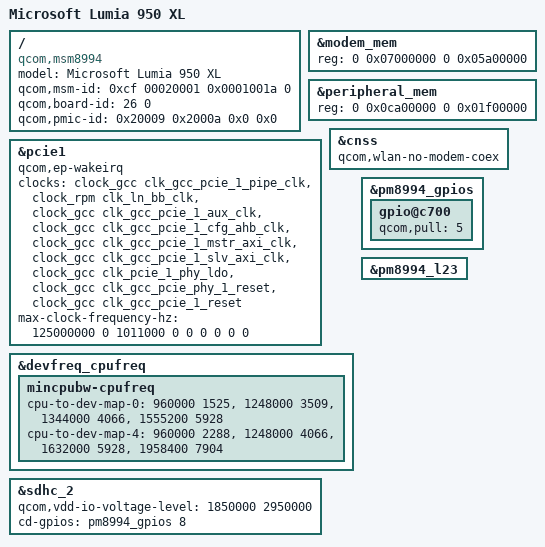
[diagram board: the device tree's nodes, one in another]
/* Copyright (c) 2014-2015, The Linux Foundation. All rights reserved.
 *
 * This program is free software; you can redistribute it and/or modify
 * it under the terms of the GNU General Public License version 2 and
 * only version 2 as published by the Free Software Foundation.
 *
 * This program is distributed in the hope that it will be useful,
 * but WITHOUT ANY WARRANTY; without even the implied warranty of
 * MERCHANTABILITY or FITNESS FOR A PARTICULAR PURPOSE.  See the
 * GNU General Public License for more details.
 */

/dts-v1/;

#include "../qcom/msm8994-v2.1.dtsi"
#include "../qcom/msm8994-pinctrl.dtsi"
#include "msm8994-chi.dtsi"
#include "cityman-audio.dtsi"

/ {
	model = "Microsoft Lumia 950 XL";
	compatible = "qcom,msm8994", "mmo,cityman";
	qcom,msm-id = <0xcf 00020001 0x0001001a 0>;
	qcom,board-id = <26 0>;
	qcom,pmic-id = <0x20009 0x2000a 0x0 0x0>;
};

/*
 * Keep the stock cityman modem load addresses out of Linux allocations.
 * ramoops uses the common region at the top of DDR bank 1, clear of the
 * modem image.
 */
&modem_mem {
	reg = <0 0x07000000 0 0x05a00000>;
};

&peripheral_mem {
	reg = <0 0x0ca00000 0 0x01f00000>;
};

/* Reset the controller as well as the PHY before enumerating QCA6174. */
&pcie1 {
	/* CNSS must power the endpoint before the first enumeration. */
	qcom,ep-wakeirq;
	clocks = <&clock_gcc clk_gcc_pcie_1_pipe_clk>,
		<&clock_rpm clk_ln_bb_clk>,
		<&clock_gcc clk_gcc_pcie_1_aux_clk>,
		<&clock_gcc clk_gcc_pcie_1_cfg_ahb_clk>,
		<&clock_gcc clk_gcc_pcie_1_mstr_axi_clk>,
		<&clock_gcc clk_gcc_pcie_1_slv_axi_clk>,
		<&clock_gcc clk_pcie_1_phy_ldo>,
		<&clock_gcc clk_gcc_pcie_phy_1_reset>,
		<&clock_gcc clk_gcc_pcie_1_reset>;
	clock-names = "pcie_1_pipe_clk", "pcie_1_ref_clk_src",
		"pcie_1_aux_clk", "pcie_1_cfg_ahb_clk",
		"pcie_1_mstr_axi_clk", "pcie_1_slv_axi_clk",
		"pcie_1_ldo", "pcie_1_phy_reset", "core_reset";
	max-clock-frequency-hz = <125000000 0 1011000 0 0 0 0 0 0>;
};

#include "cityman-thermal.dtsi"

/* The stock MPSS asserts in coex_qmb.c with the WLAN WCI-2 coexistence on. */
&cnss {
	qcom,wlan-no-modem-coex;
};

/* DDR floor follows the CPU frequency, so input boosts and launch locks
 * also raise the memory bus (the msm8994 default keeps 200 MHz up to
 * 1.824 GHz). Values are entries of the cpubw bandwidth table. */
&devfreq_cpufreq {
	mincpubw-cpufreq {
		cpu-to-dev-map-0 =
			<  960000  1525 >,
			< 1248000  3509 >,
			< 1344000  4066 >,
			< 1555200  5928 >;
		cpu-to-dev-map-4 =
			<  960000  2288 >,
			< 1248000  4066 >,
			< 1632000  5928 >,
			< 1958400  7904 >;
	};
};

/*
 * microSD (sdhc_2), from the Windows ACPI description of \_SB.SDC2: the card
 * detect line (PM8994 GPIO 8) has no pull, and the low I/O level on LDO13 is
 * 1.85 V, the regulator's floor (common/regulator.dtsi); a 1.8 V request on
 * L13 would fail the UHS voltage switch.
 *
 * The detect line is high with a card in the tray and low with the tray
 * removed (measured on a cityman, 30/10/2026). Declared active low, the slot
 * saw the card for a moment while the tray went in and then dropped it as
 * removed, so the polarity is active high.
 */
&pm8994_gpios {
	gpio@c700 { /* GPIO 8: SD card detect */
		qcom,pull = <5>;		/* no pull */
	};
};

&sdhc_2 {
	qcom,vdd-io-voltage-level = <1850000 2950000>;
	cd-gpios = <&pm8994_gpios 8 0x0>;	/* active high */
};

/*
 * L23 feeds only the rear camera's focus actuator (cam_vaf). Kept always on,
 * it powers the actuator while the camera is closed and its driver has not
 * set it up, and the voice coil whistles. The camera and actuator drivers
 * switch it on when a session starts.
 */
&pm8994_l23 {
	/delete-property/ regulator-always-on;
};
